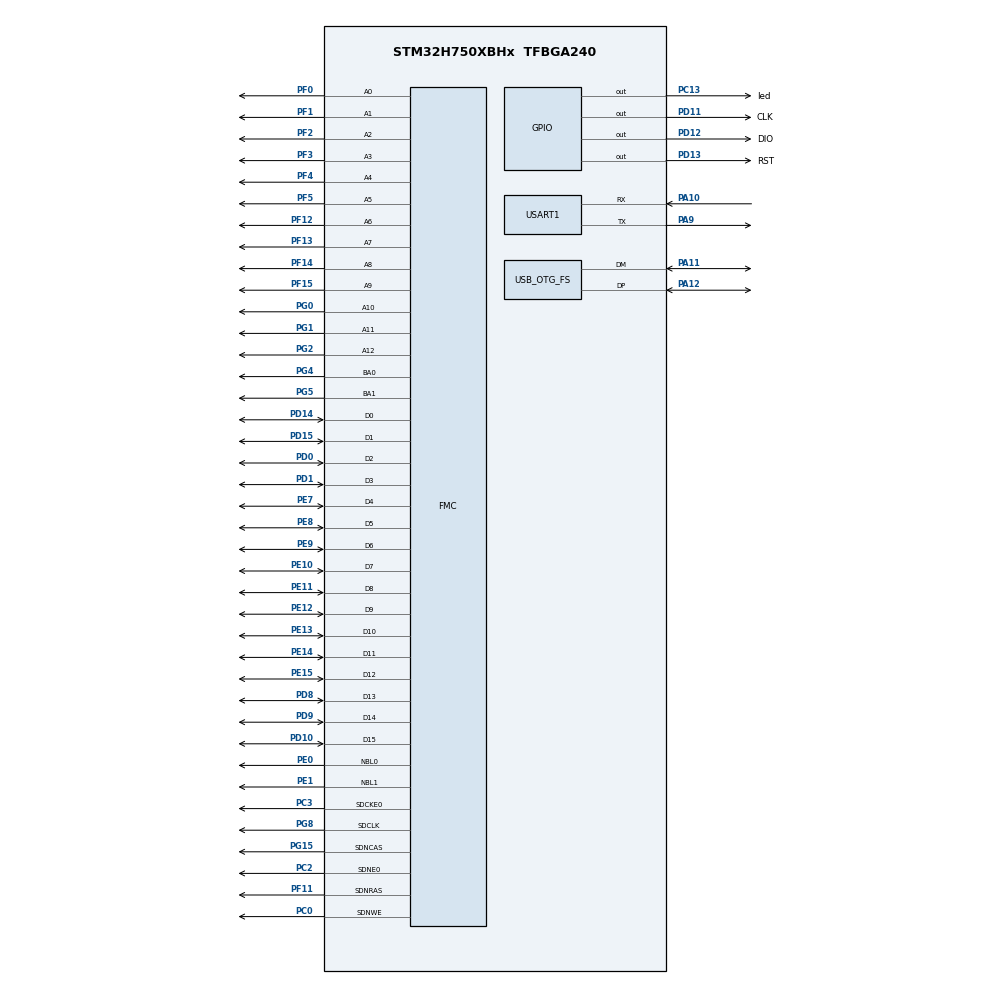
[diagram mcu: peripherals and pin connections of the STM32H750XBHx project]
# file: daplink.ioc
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CORTEX_M7.AccessPermission-Cortex_Memory_Protection_Unit_Region0_Settings=MPU_REGION_FULL_ACCESS
CORTEX_M7.AccessPermission-Cortex_Memory_Protection_Unit_Region1_Settings=MPU_REGION_PRIV_RW
CORTEX_M7.AccessPermission-Cortex_Memory_Protection_Unit_Region2_Settings=MPU_REGION_PRIV_RW
CORTEX_M7.AccessPermission-Cortex_Memory_Protection_Unit_Region3_Settings=MPU_REGION_PRIV_RW
CORTEX_M7.AccessPermission-Cortex_Memory_Protection_Unit_Region4_Settings=MPU_REGION_PRIV_RW
CORTEX_M7.BaseAddress-Cortex_Memory_Protection_Unit_Region0_Settings=0x08000000
CORTEX_M7.BaseAddress-Cortex_Memory_Protection_Unit_Region1_Settings=0x20000000
CORTEX_M7.BaseAddress-Cortex_Memory_Protection_Unit_Region2_Settings=0x24000000
CORTEX_M7.BaseAddress-Cortex_Memory_Protection_Unit_Region3_Settings=0x38000000
CORTEX_M7.BaseAddress-Cortex_Memory_Protection_Unit_Region4_Settings=0xC0000000
CORTEX_M7.CPU_DCache=Enabled
CORTEX_M7.CPU_ICache=Enabled
CORTEX_M7.Enable-Cortex_Memory_Protection_Unit_Region0_Settings=MPU_REGION_ENABLE
CORTEX_M7.Enable-Cortex_Memory_Protection_Unit_Region1_Settings=MPU_REGION_ENABLE
CORTEX_M7.Enable-Cortex_Memory_Protection_Unit_Region2_Settings=MPU_REGION_ENABLE
CORTEX_M7.Enable-Cortex_Memory_Protection_Unit_Region3_Settings=MPU_REGION_ENABLE
CORTEX_M7.Enable-Cortex_Memory_Protection_Unit_Region4_Settings=MPU_REGION_ENABLE
CORTEX_M7.IsBufferable-Cortex_Memory_Protection_Unit_Region1_Settings=MPU_ACCESS_BUFFERABLE
CORTEX_M7.IsBufferable-Cortex_Memory_Protection_Unit_Region2_Settings=MPU_ACCESS_BUFFERABLE
CORTEX_M7.IsBufferable-Cortex_Memory_Protection_Unit_Region4_Settings=MPU_ACCESS_BUFFERABLE
CORTEX_M7.IsCacheable-Cortex_Memory_Protection_Unit_Region0_Settings=MPU_ACCESS_CACHEABLE
CORTEX_M7.IsCacheable-Cortex_Memory_Protection_Unit_Region1_Settings=MPU_ACCESS_CACHEABLE
CORTEX_M7.IsCacheable-Cortex_Memory_Protection_Unit_Region2_Settings=MPU_ACCESS_CACHEABLE
CORTEX_M7.IsCacheable-Cortex_Memory_Protection_Unit_Region4_Settings=MPU_ACCESS_CACHEABLE
CORTEX_M7.IsShareable-Cortex_Memory_Protection_Unit_Region0_Settings=MPU_ACCESS_SHAREABLE
CORTEX_M7.IsShareable-Cortex_Memory_Protection_Unit_Region1_Settings=MPU_ACCESS_SHAREABLE
CORTEX_M7.IsShareable-Cortex_Memory_Protection_Unit_Region2_Settings=MPU_ACCESS_SHAREABLE
CORTEX_M7.IsShareable-Cortex_Memory_Protection_Unit_Region4_Settings=MPU_ACCESS_SHAREABLE
CORTEX_M7.MPU_Control=MPU_PRIVILEGED_DEFAULT
CORTEX_M7.Size-Cortex_Memory_Protection_Unit_Region0_Settings=MPU_REGION_SIZE_128KB
CORTEX_M7.Size-Cortex_Memory_Protection_Unit_Region1_Settings=MPU_REGION_SIZE_128KB
CORTEX_M7.Size-Cortex_Memory_Protection_Unit_Region2_Settings=MPU_REGION_SIZE_512KB
CORTEX_M7.Size-Cortex_Memory_Protection_Unit_Region3_Settings=MPU_REGION_SIZE_64KB
CORTEX_M7.Size-Cortex_Memory_Protection_Unit_Region4_Settings=MPU_REGION_SIZE_32MB
CORTEX_M7.TypeExtField-Cortex_Memory_Protection_Unit_Region3_Settings=MPU_TEX_LEVEL1
CORTEX_M7.default_mode_Activation=0
Dma.Request0=USART1_TX
Dma.USART1_TX.0.Direction=DMA_MEMORY_TO_PERIPH
Dma.USART1_TX.0.EventEnable=DISABLE
Dma.USART1_TX.0.FIFOMode=DMA_FIFOMODE_DISABLE
Dma.USART1_TX.0.Instance=DMA1_Stream0
Dma.USART1_TX.0.MemDataAlignment=DMA_MDATAALIGN_BYTE
Dma.USART1_TX.0.MemInc=DMA_MINC_ENABLE
Dma.USART1_TX.0.Mode=DMA_NORMAL
Dma.USART1_TX.0.PeriphDataAlignment=DMA_PDATAALIGN_BYTE
Dma.USART1_TX.0.PeriphInc=DMA_PINC_DISABLE
Dma.USART1_TX.0.Polarity=HAL_DMAMUX_REQ_GEN_RISING
Dma.USART1_TX.0.Priority=DMA_PRIORITY_MEDIUM
Dma.USART1_TX.0.RequestNumber=1
Dma.USART1_TX.0.SignalID=NONE
Dma.USART1_TX.0.SyncEnable=DISABLE
Dma.USART1_TX.0.SyncPolarity=HAL_DMAMUX_SYNC_NO_EVENT
Dma.USART1_TX.0.SyncRequestNumber=1
Dma.USART1_TX.0.SyncSignalID=NONE
FMC.CASLatency1=FMC_SDRAM_CAS_LATENCY_3
FMC.ColumnBitsNumber1=FMC_SDRAM_COLUMN_BITS_NUM_9
FMC.ExitSelfRefreshDelay1=7
FMC.LoadToActiveDelay1=2
FMC.RCDDelay1=2
FMC.RPDelay1=2
FMC.RPDelay2=2
FMC.ReadBurst1=FMC_SDRAM_RBURST_ENABLE
FMC.ReadBurst2=FMC_SDRAM_RBURST_ENABLE
FMC.ReadPipeDelay1=FMC_SDRAM_RPIPE_DELAY_1
FMC.ReadPipeDelay2=FMC_SDRAM_RPIPE_DELAY_1
FMC.RowCycleDelay1=7
FMC.RowCycleDelay2=7
FMC.SDClockPeriod1=FMC_SDRAM_CLOCK_PERIOD_2
FMC.SDClockPeriod2=FMC_SDRAM_CLOCK_PERIOD_2
FMC.SelfRefreshTime1=4
FMC.WriteRecoveryTime1=3
Mcu.Family=STM32H7
Mcu.Name=STM32H750XBHx
Mcu.Package=TFBGA240
NVIC.DMA1_Stream0_IRQn=true\:0\:0\:false\:false\:true\:false\:true\:true
NVIC.PriorityGroup=NVIC_PRIORITYGROUP_4
PA10.Mode=Asynchronous
PA10.Signal=USART1_RX
PA11.Mode=Device_Only
PA11.Signal=USB_OTG_FS_DM
PA12.Mode=Device_Only
PA12.Signal=USB_OTG_FS_DP
PA9.Mode=Asynchronous
PA9.Signal=USART1_TX
PC0.Signal=FMC_SDNWE
PC13.GPIO_Label=led
PC13.GPIO_PuPd=GPIO_NOPULL
PC13.Signal=GPIO_Output
PC2.Mode=SdramChipSelect1_1
PC2.Signal=FMC_SDNE0
PC3.Mode=SdramChipSelect1_1
PC3.Signal=FMC_SDCKE0
PD0.Signal=FMC_D2_DA2
PD1.Signal=FMC_D3_DA3
PD10.Signal=FMC_D15_DA15
PD11.GPIO_Label=CLK
PD11.GPIO_PuPd=GPIO_PULLUP
PD11.GPIO_Speed=GPIO_SPEED_FREQ_VERY_HIGH
PD11.PinState=GPIO_PIN_RESET
PD11.Signal=GPIO_Output
PD12.GPIO_Label=DIO
PD12.GPIO_PuPd=GPIO_PULLUP
PD12.GPIO_Speed=GPIO_SPEED_FREQ_VERY_HIGH
PD12.Signal=GPIO_Output
PD13.GPIO_Label=RST
PD13.GPIO_PuPd=GPIO_PULLUP
PD13.GPIO_Speed=GPIO_SPEED_FREQ_VERY_HIGH
PD13.PinState=GPIO_PIN_SET
PD13.Signal=GPIO_Output
PD14.Signal=FMC_D0_DA0
PD15.Signal=FMC_D1_DA1
PD8.Signal=FMC_D13_DA13
PD9.Signal=FMC_D14_DA14
PE0.Signal=FMC_NBL0
PE1.Signal=FMC_NBL1
PE10.Signal=FMC_D7_DA7
PE11.Signal=FMC_D8_DA8
PE12.Signal=FMC_D9_DA9
PE13.Signal=FMC_D10_DA10
PE14.Signal=FMC_D11_DA11
PE15.Signal=FMC_D12_DA12
PE7.Signal=FMC_D4_DA4
PE8.Signal=FMC_D5_DA5
PE9.Signal=FMC_D6_DA6
PF0.Signal=FMC_A0
PF1.Signal=FMC_A1
PF11.Signal=FMC_SDNRAS
PF12.Signal=FMC_A6
PF13.Signal=FMC_A7
PF14.Signal=FMC_A8
PF15.Signal=FMC_A9
PF2.Signal=FMC_A2
PF3.Signal=FMC_A3
PF4.Signal=FMC_A4
PF5.Signal=FMC_A5
PG0.Signal=FMC_A10
PG1.Signal=FMC_A11
PG15.Signal=FMC_SDNCAS
PG2.Signal=FMC_A12
PG4.Signal=FMC_A14_BA0
PG5.Signal=FMC_A15_BA1
PG8.Signal=FMC_SDCLK
PH0-OSC_IN\ (PH0).Mode=HSE-External-Oscillator
PH0-OSC_IN\ (PH0).Signal=RCC_OSC_IN
PH1-OSC_OUT\ (PH1).Mode=HSE-External-Oscillator
PH1-OSC_OUT\ (PH1).Signal=RCC_OSC_OUT
ProjectManager.HeapSize=0x2000
ProjectManager.StackSize=0x4000
ProjectManager.TargetToolchain=CMake
RCC.ADCFreq_Value=50390625
RCC.APB1Freq_Value=120000000
RCC.APB2Freq_Value=120000000
RCC.APB3Freq_Value=120000000
RCC.APB4Freq_Value=120000000
RCC.CortexFreq_Value=480000000
RCC.D1PPRE=RCC_APB3_DIV2
RCC.D2PPRE1=RCC_APB1_DIV2
RCC.D2PPRE2=RCC_APB2_DIV2
RCC.D3PPRE=RCC_APB4_DIV2
RCC.DIVM1=5
RCC.DIVM3=5
RCC.DIVN1=192
RCC.DIVN3=100
RCC.DIVQ1=20
RCC.DIVQ3=50
RCC.HCLKFreq_Value=240000000
RCC.HPRE=RCC_HCLK_DIV2
RCC.PLL2FRACN=0
RCC.PLL3FRACN=0
RCC.PLLFRACN=0
RCC.PLLSourceVirtual=RCC_PLLSOURCE_HSE
RCC.SYSCLKFreq_VALUE=480000000
RCC.SYSCLKSource=RCC_SYSCLKSOURCE_PLLCLK
RCC.USBFreq_Value=48000000
SH.FMC_A0.0=FMC_A0,13b-sda1
SH.FMC_A1.0=FMC_A1,13b-sda1
SH.FMC_A10.0=FMC_A10,13b-sda1
SH.FMC_A11.0=FMC_A11,13b-sda1
SH.FMC_A12.0=FMC_A12,13b-sda1
SH.FMC_A14_BA0.0=FMC_BA0,FourSdramBanks1
SH.FMC_A15_BA1.0=FMC_BA1,FourSdramBanks1
SH.FMC_A2.0=FMC_A2,13b-sda1
SH.FMC_A3.0=FMC_A3,13b-sda1
SH.FMC_A4.0=FMC_A4,13b-sda1
SH.FMC_A5.0=FMC_A5,13b-sda1
SH.FMC_A6.0=FMC_A6,13b-sda1
SH.FMC_A7.0=FMC_A7,13b-sda1
SH.FMC_A8.0=FMC_A8,13b-sda1
SH.FMC_A9.0=FMC_A9,13b-sda1
SH.FMC_D0_DA0.0=FMC_D0,sd-16b-d1
SH.FMC_D10_DA10.0=FMC_D10,sd-16b-d1
SH.FMC_D11_DA11.0=FMC_D11,sd-16b-d1
SH.FMC_D12_DA12.0=FMC_D12,sd-16b-d1
SH.FMC_D13_DA13.0=FMC_D13,sd-16b-d1
SH.FMC_D14_DA14.0=FMC_D14,sd-16b-d1
SH.FMC_D15_DA15.0=FMC_D15,sd-16b-d1
SH.FMC_D1_DA1.0=FMC_D1,sd-16b-d1
SH.FMC_D2_DA2.0=FMC_D2,sd-16b-d1
SH.FMC_D3_DA3.0=FMC_D3,sd-16b-d1
SH.FMC_D4_DA4.0=FMC_D4,sd-16b-d1
SH.FMC_D5_DA5.0=FMC_D5,sd-16b-d1
SH.FMC_D6_DA6.0=FMC_D6,sd-16b-d1
SH.FMC_D7_DA7.0=FMC_D7,sd-16b-d1
SH.FMC_D8_DA8.0=FMC_D8,sd-16b-d1
SH.FMC_D9_DA9.0=FMC_D9,sd-16b-d1
SH.FMC_NBL0.0=FMC_NBL0,Sd2ByteEnable1
SH.FMC_NBL1.0=FMC_NBL1,Sd2ByteEnable1
SH.FMC_SDCLK.0=FMC_SDCLK,13b-sda1
SH.FMC_SDNCAS.0=FMC_SDNCAS,13b-sda1
SH.FMC_SDNRAS.0=FMC_SDNRAS,13b-sda1
SH.FMC_SDNWE.0=FMC_SDNWE,13b-sda1
USART1.VirtualMode-Asynchronous=VM_ASYNC
USB_OTG_FS.VirtualMode=Device_Only
VP_MEMORYMAP_VS_MEMORYMAP.Mode=CurAppReg
board=custom

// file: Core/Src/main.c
/* USER CODE BEGIN Header */
/**
  ******************************************************************************
  * @file           : main.c
  * @brief          : Main program body
  ******************************************************************************
  * @attention
  *
  * Copyright (c) 2026 STMicroelectronics.
  * All rights reserved.
  *
  * This software is licensed under terms that can be found in the LICENSE file
  * in the root directory of this software component.
  * If no LICENSE file comes with this software, it is provided AS-IS.
  *
  ******************************************************************************
  */
/* USER CODE END Header */
#include "main.h"
#include "dma.h"
#include "usart.h"
#include "usb_otg.h"
#include "gpio.h"
#include "fmc.h"

/* USER CODE BEGIN Includes */
#include "dap_main.h"
/* USER CODE END Includes */

void SystemClock_Config(void);
static void MPU_Config(void);

/* USER CODE BEGIN 0 */
/* Debug console: redirect printf to USART1 (polling mode) */
int __io_putchar(int ch)
{
  while (!(USART1->ISR & USART_ISR_TXE_TXFNF)) {}
  USART1->TDR = (ch & 0xFF);
  return ch;
}

int __io_getchar(void)
{
  while (!(USART1->ISR & USART_ISR_RXNE_RXFNE)) {}
  return (int)(USART1->RDR & 0xFF);
}
/* USER CODE END 0 */

int main(void)
{

  /* MPU Configuration--------------------------------------------------------*/
  MPU_Config();

  /* Enable the CPU Cache */

  /* Enable I-Cache---------------------------------------------------------*/
  SCB_EnableICache();

  /* Enable D-Cache---------------------------------------------------------*/
  SCB_EnableDCache();

  /* MCU Configuration--------------------------------------------------------*/

  /* Reset of all peripherals, Initializes the Flash interface and the Systick. */
  HAL_Init();

  /* Configure the system clock */
  SystemClock_Config();

  /* Initialize all configured peripherals */
  MX_GPIO_Init();
  MX_DMA_Init();
  MX_FMC_Init();
  MX_USART1_UART_Init();
  MX_USB_OTG_FS_PCD_Init();
  /* USER CODE BEGIN 2 */
  chry_dap_init(0, USB_OTG_FS_PERIPH_BASE);
  /* Enable USB interrupt (CherryUSB DWC2 driver does not enable it) */
  HAL_NVIC_SetPriority(OTG_FS_IRQn, 0, 0);
  HAL_NVIC_EnableIRQ(OTG_FS_IRQn);
  printf("DAPLink: CherryUSB initialized\r\n");
  /* USER CODE END 2 */

  /* Infinite loop */
  /* USER CODE BEGIN WHILE */
  while (1)
  {
    chry_dap_handle();
    chry_dap_usb2uart_handle();
    /* USER CODE END WHILE */

  }
}

void SystemClock_Config(void)
{
  RCC_OscInitTypeDef RCC_OscInitStruct = {0};
  RCC_ClkInitTypeDef RCC_ClkInitStruct = {0};

  /** Supply configuration update enable
  */
  HAL_PWREx_ConfigSupply(PWR_LDO_SUPPLY);

  /** Configure the main internal regulator output voltage
  */
  __HAL_PWR_VOLTAGESCALING_CONFIG(PWR_REGULATOR_VOLTAGE_SCALE0);

  while(!__HAL_PWR_GET_FLAG(PWR_FLAG_VOSRDY)) {}

  /** Initializes the RCC Oscillators according to the specified parameters
  * in the RCC_OscInitTypeDef structure.
  */
  RCC_OscInitStruct.OscillatorType = RCC_OSCILLATORTYPE_HSE;
  RCC_OscInitStruct.HSEState = RCC_HSE_ON;
  RCC_OscInitStruct.PLL.PLLState = RCC_PLL_ON;
  RCC_OscInitStruct.PLL.PLLSource = RCC_PLLSOURCE_HSE;
  RCC_OscInitStruct.PLL.PLLM = 5;
  RCC_OscInitStruct.PLL.PLLN = 192;
  RCC_OscInitStruct.PLL.PLLP = 2;
  RCC_OscInitStruct.PLL.PLLQ = 20;
  RCC_OscInitStruct.PLL.PLLR = 2;
  RCC_OscInitStruct.PLL.PLLRGE = RCC_PLL1VCIRANGE_2;
  RCC_OscInitStruct.PLL.PLLVCOSEL = RCC_PLL1VCOWIDE;
  RCC_OscInitStruct.PLL.PLLFRACN = 0;
  if (HAL_RCC_OscConfig(&RCC_OscInitStruct) != HAL_OK)
  {
    Error_Handler();
  }

  /** Initializes the CPU, AHB and APB buses clocks
  */
  RCC_ClkInitStruct.ClockType = RCC_CLOCKTYPE_HCLK|RCC_CLOCKTYPE_SYSCLK
                              |RCC_CLOCKTYPE_PCLK1|RCC_CLOCKTYPE_PCLK2
                              |RCC_CLOCKTYPE_D3PCLK1|RCC_CLOCKTYPE_D1PCLK1;
  RCC_ClkInitStruct.SYSCLKSource = RCC_SYSCLKSOURCE_PLLCLK;
  RCC_ClkInitStruct.SYSCLKDivider = RCC_SYSCLK_DIV1;
  RCC_ClkInitStruct.AHBCLKDivider = RCC_HCLK_DIV2;
  RCC_ClkInitStruct.APB3CLKDivider = RCC_APB3_DIV2;
  RCC_ClkInitStruct.APB1CLKDivider = RCC_APB1_DIV2;
  RCC_ClkInitStruct.APB2CLKDivider = RCC_APB2_DIV2;
  RCC_ClkInitStruct.APB4CLKDivider = RCC_APB4_DIV2;

  if (HAL_RCC_ClockConfig(&RCC_ClkInitStruct, FLASH_LATENCY_4) != HAL_OK)
  {
    Error_Handler();
  }
}

 /* MPU Configuration */

void MPU_Config(void)
{
  MPU_Region_InitTypeDef MPU_InitStruct = {0};

  /* Disables the MPU */
  HAL_MPU_Disable();

  /** Initializes and configures the Region and the memory to be protected
  */
  MPU_InitStruct.Enable = MPU_REGION_ENABLE;
  MPU_InitStruct.Number = MPU_REGION_NUMBER0;
  MPU_InitStruct.BaseAddress = 0x08000000;
  MPU_InitStruct.Size = MPU_REGION_SIZE_128KB;
  MPU_InitStruct.SubRegionDisable = 0x0;
  MPU_InitStruct.TypeExtField = MPU_TEX_LEVEL0;
  MPU_InitStruct.AccessPermission = MPU_REGION_FULL_ACCESS;
  MPU_InitStruct.DisableExec = MPU_INSTRUCTION_ACCESS_ENABLE;
  MPU_InitStruct.IsShareable = MPU_ACCESS_SHAREABLE;
  MPU_InitStruct.IsCacheable = MPU_ACCESS_CACHEABLE;
  MPU_InitStruct.IsBufferable = MPU_ACCESS_NOT_BUFFERABLE;

  HAL_MPU_ConfigRegion(&MPU_InitStruct);

  /** Initializes and configures the Region and the memory to be protected
  */
  MPU_InitStruct.Number = MPU_REGION_NUMBER1;
  MPU_InitStruct.BaseAddress = 0x20000000;
  MPU_InitStruct.AccessPermission = MPU_REGION_PRIV_RW;
  MPU_InitStruct.IsBufferable = MPU_ACCESS_BUFFERABLE;

  HAL_MPU_ConfigRegion(&MPU_InitStruct);

  /** Initializes and configures the Region and the memory to be protected
  */
  MPU_InitStruct.Number = MPU_REGION_NUMBER2;
  MPU_InitStruct.BaseAddress = 0x24000000;
  MPU_InitStruct.Size = MPU_REGION_SIZE_512KB;

  HAL_MPU_ConfigRegion(&MPU_InitStruct);

  /** Initializes and configures the Region and the memory to be protected
  */
  MPU_InitStruct.Number = MPU_REGION_NUMBER3;
  MPU_InitStruct.BaseAddress = 0x38000000;
  MPU_InitStruct.Size = MPU_REGION_SIZE_64KB;
  MPU_InitStruct.TypeExtField = MPU_TEX_LEVEL1;
  MPU_InitStruct.IsShareable = MPU_ACCESS_NOT_SHAREABLE;
  MPU_InitStruct.IsCacheable = MPU_ACCESS_NOT_CACHEABLE;
  MPU_InitStruct.IsBufferable = MPU_ACCESS_NOT_BUFFERABLE;

  HAL_MPU_ConfigRegion(&MPU_InitStruct);

  /** Initializes and configures the Region and the memory to be protected
  */
  MPU_InitStruct.Number = MPU_REGION_NUMBER4;
  MPU_InitStruct.BaseAddress = 0xC0000000;
  MPU_InitStruct.Size = MPU_REGION_SIZE_32MB;
  MPU_InitStruct.TypeExtField = MPU_TEX_LEVEL0;
  MPU_InitStruct.IsShareable = MPU_ACCESS_SHAREABLE;
  MPU_InitStruct.IsCacheable = MPU_ACCESS_CACHEABLE;
  MPU_InitStruct.IsBufferable = MPU_ACCESS_BUFFERABLE;

  HAL_MPU_ConfigRegion(&MPU_InitStruct);
  /* Enables the MPU */
  HAL_MPU_Enable(MPU_PRIVILEGED_DEFAULT);

}

void Error_Handler(void)
{
  __disable_irq();
  while (1)
  {
  }
}
